VERSION ""

NS_ :

BS_:

BU_: BMS Third_Party_Device

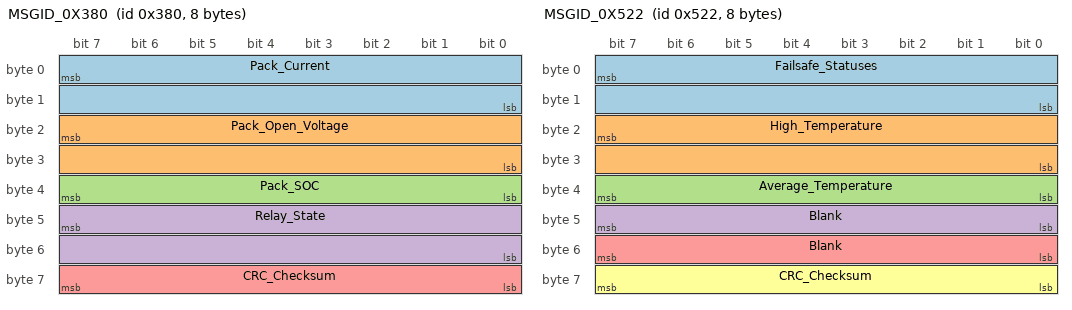
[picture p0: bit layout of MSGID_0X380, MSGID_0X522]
BO_ 896 MSGID_0X380: 8 BMS
 SG_ Pack_Current : 7|16@0+ (0.1,0) [0|0] "Amps"  Third_Party_Device
 SG_ Pack_Open_Voltage : 23|16@0+ (0.1,0) [0|0] "Volts"  Third_Party_Device
 SG_ Pack_SOC : 39|8@0+ (0.5,0) [0|0] "Percent"  Third_Party_Device
 SG_ Relay_State : 47|16@0+ (1.0,0) [0|0] ""  Third_Party_Device
 SG_ CRC_Checksum : 63|8@0+ (1.0,1720) [0|0] ""  Third_Party_Device

BO_ 1314 MSGID_0X522: 8 BMS
 SG_ Failsafe_Statuses : 7|16@0+ (1.0,0) [0|0] ""  Third_Party_Device
 SG_ High_Temperature : 23|16@0+ (1.0,0) [0|0] "Celsius"  Third_Party_Device
 SG_ Average_Temperature : 39|8@0+ (1.0,0) [0|0] "Celsius"  Third_Party_Device
 SG_ Blank : 47|8@0+ (1.0,0) [0|0] ""  Third_Party_Device
 SG_ Blank : 55|8@0+ (1.0,0) [0|0] ""  Third_Party_Device
 SG_ CRC_Checksum : 63|8@0+ (1.0,1721) [0|0] ""  Third_Party_Device

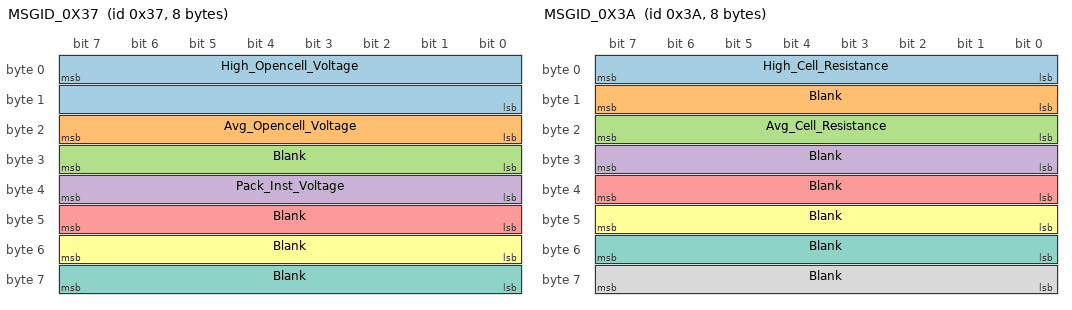
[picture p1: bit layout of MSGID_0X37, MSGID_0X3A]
BO_ 55 MSGID_0X37: 8 BMS
 SG_ High_Opencell_Voltage : 7|16@0+ (1.0E-4,0) [0|0] "Volts"  Third_Party_Device
 SG_ Avg_Opencell_Voltage : 23|8@0+ (1.0E-4,0) [0|0] "Volts"  Third_Party_Device
 SG_ Blank : 31|8@0+ (1.0,0) [0|0] ""  Third_Party_Device
 SG_ Pack_Inst_Voltage : 39|8@0+ (0.1,0) [0|0] "Volts"  Third_Party_Device
 SG_ Blank : 47|8@0+ (1.0,0) [0|0] ""  Third_Party_Device
 SG_ Blank : 55|8@0+ (1.0,0) [0|0] ""  Third_Party_Device
 SG_ Blank : 63|8@0+ (1.0,0) [0|0] ""  Third_Party_Device

BO_ 58 MSGID_0X3A: 8 BMS
 SG_ High_Cell_Resistance : 7|8@0+ (0.01,0) [0|0] "mOhm"  Third_Party_Device
 SG_ Blank : 15|8@0+ (1.0,0) [0|0] ""  Third_Party_Device
 SG_ Avg_Cell_Resistance : 23|8@0+ (0.01,0) [0|0] "mOhm"  Third_Party_Device
 SG_ Blank : 31|8@0+ (1.0,0) [0|0] ""  Third_Party_Device
 SG_ Blank : 39|8@0+ (1.0,0) [0|0] ""  Third_Party_Device
 SG_ Blank : 47|8@0+ (1.0,0) [0|0] ""  Third_Party_Device
 SG_ Blank : 55|8@0+ (1.0,0) [0|0] ""  Third_Party_Device
 SG_ Blank : 63|8@0+ (1.0,0) [0|0] ""  Third_Party_Device

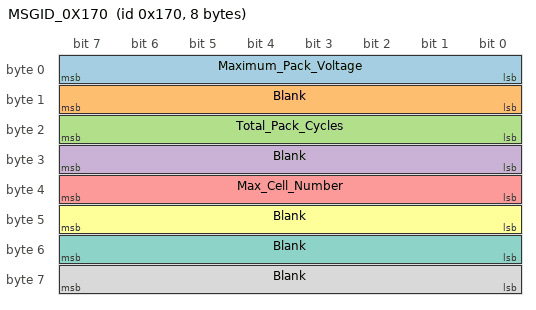
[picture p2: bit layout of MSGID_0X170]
BO_ 368 MSGID_0X170: 8 BMS
 SG_ Maximum_Pack_Voltage : 7|8@0+ (0.1,0) [0|0] "Volts"  Third_Party_Device
 SG_ Blank : 15|8@0+ (1.0,0) [0|0] ""  Third_Party_Device
 SG_ Total_Pack_Cycles : 23|8@0+ (1.0,0) [0|0] "Num"  Third_Party_Device
 SG_ Blank : 31|8@0+ (1.0,0) [0|0] ""  Third_Party_Device
 SG_ Max_Cell_Number : 39|8@0+ (1.0,0) [0|0] "Num"  Third_Party_Device
 SG_ Blank : 47|8@0+ (1.0,0) [0|0] ""  Third_Party_Device
 SG_ Blank : 55|8@0+ (1.0,0) [0|0] ""  Third_Party_Device
 SG_ Blank : 63|8@0+ (1.0,0) [0|0] ""  Third_Party_Device

CM_ BO_ 896 "This ID Transmits at 8 ms.";
CM_ BO_ 1314 "This ID Transmits at 104 ms.";
CM_ BO_ 55 "This ID Transmits at 8 ms.";
CM_ BO_ 58 "This ID Transmits at 8 ms.";
CM_ BO_ 368 "This ID Transmits at 8 ms.";
